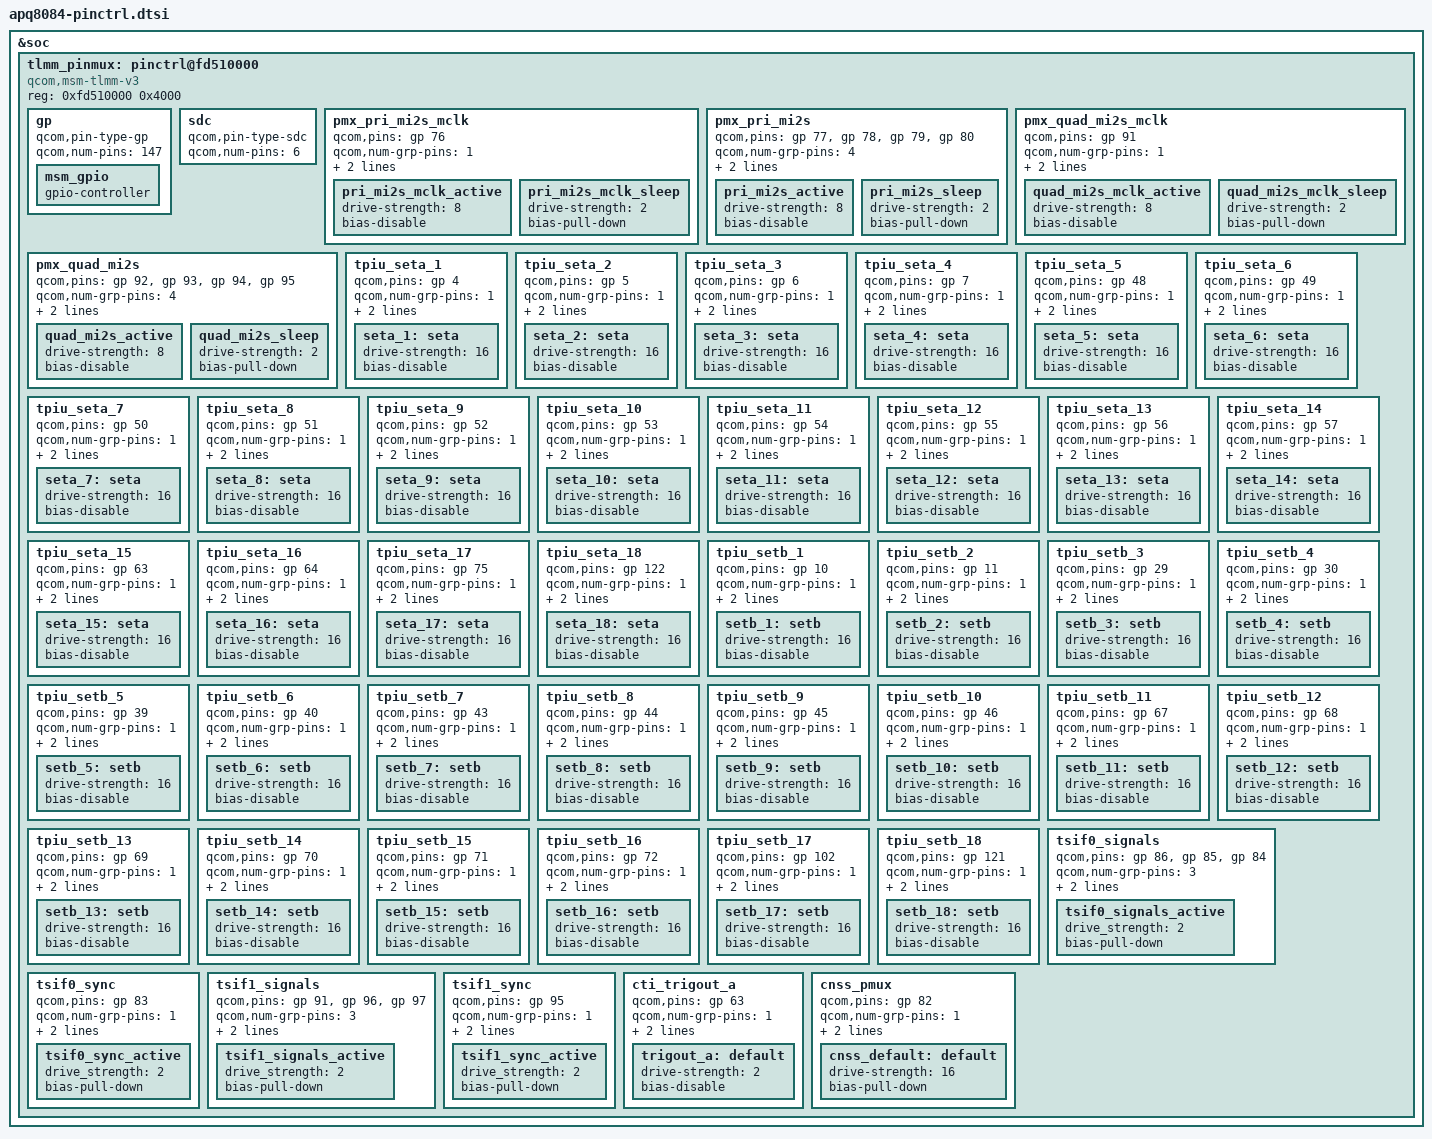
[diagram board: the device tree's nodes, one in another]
/* Copyright (c) 2014, The Linux Foundation. All rights reserved.
 *
 * This program is free software; you can redistribute it and/or modify
 * it under the terms of the GNU General Public License version 2 and
 * only version 2 as published by the Free Software Foundation.
 *
 * This program is distributed in the hope that it will be useful,
 * but WITHOUT ANY WARRANTY; without even the implied warranty of
 * MERCHANTABILITY or FITNESS FOR A PARTICULAR PURPOSE.  See the
 * GNU General Public License for more details.
 */

&soc {
	tlmm_pinmux: pinctrl@fd510000 {
		compatible = "qcom,msm-tlmm-v3";
		reg = <0xfd510000 0x4000>;

		/*General purpose pins*/
		gp: gp {
			qcom,pin-type-gp;
			qcom,num-pins = <147>;
			#qcom,pin-cells = <1>;
			msm_gpio: msm_gpio {
				gpio-controller;
				#gpio-cells = <2>;
			};
		};
		/* SDC pin type */
		sdc: sdc {
			qcom,pin-type-sdc;
			/* 0-2 for sdc1 3-5 for sdc2 */
			qcom,num-pins = <6>;
			/* Order of pins */
			/* CLK -> 0 */
			/* CMD -> 1 */
			/* DATA -> 2 */
			#qcom,pin-cells = <1>;
		};

		pmx_pri_mi2s_mclk {
			qcom,pins = <&gp 76>;
			qcom,num-grp-pins = <1>;
			qcom,pin-func = <1>;
			label = "pri_mi2s_mclk";
			pri_mi2s_mclk_active: pri_mi2s_mclk_active {
				drive-strength = <8>;	/* 8 MA */
				bias-disable;		/* No PULL */
		        };
			pri_mi2s_mclk_sleep: pri_mi2s_mclk_sleep {
				drive-strength = <2>;	/* 2 MA */
				bias-pull-down;		/* PULL DOWN */
		        };
		};

		pmx_pri_mi2s {
			qcom,pins = <&gp 77>, <&gp 78>, <&gp 79>, <&gp 80>;
			qcom,num-grp-pins = <4>;
			qcom,pin-func = <1>;
			label = "pri_mi2s";
			pri_mi2s_active: pri_mi2s_active {
				drive-strength = <8>;	/* 8 MA */
				bias-disable;		/* No PULL */
		        };
			pri_mi2s_sleep: pri_mi2s_sleep {
				drive-strength = <2>;	/* 2 MA */
				bias-pull-down;		/* PULL DOWN */
		        };
		};

		pmx_quad_mi2s_mclk {
			qcom,pins = <&gp 91>;
			qcom,num-grp-pins = <1>;
			qcom,pin-func = <1>;
			label = "quad_mi2s_mclk";
			quad_mi2s_mclk_active: quad_mi2s_mclk_active {
				drive-strength = <8>;	/* 8 MA */
				bias-disable;		/* No PULL */
		        };
			quad_mi2s_mclk_sleep: quad_mi2s_mclk_sleep {
				drive-strength = <2>;	/* 2 MA */
				bias-pull-down;		/* PULL DOWN */
		        };
		};

		pmx_quad_mi2s {
			qcom,pins = <&gp 92>, <&gp 93>, <&gp 94>, <&gp 95>;
			qcom,num-grp-pins = <4>;
			qcom,pin-func = <1>;
			label = "quad_mi2s";
			quad_mi2s_active: quad_mi2s_active {
				drive-strength = <8>;	/* 8 MA */
				bias-disable;		/* No PULL */
		        };
			quad_mi2s_sleep: quad_mi2s_sleep {
				drive-strength = <2>;	/* 2 MA */
				bias-pull-down;		/* PULL DOWN */
		        };
		};

		/* CoreSight */
		tpiu_seta_1 {
			qcom,pins = <&gp 4>;
			qcom,num-grp-pins = <1>;
			qcom,pin-func = <4>;
			label = "tpiu-seta-1";
			seta_1: seta {
				drive-strength = <16>;
				bias-disable;
			};
		};

		tpiu_seta_2 {
			qcom,pins = <&gp 5>;
			qcom,num-grp-pins = <1>;
			qcom,pin-func = <4>;
			label = "tpiu-seta-2";
			seta_2: seta {
				drive-strength = <16>;
				bias-disable;
			};
		};

		tpiu_seta_3 {
			qcom,pins = <&gp 6>;
			qcom,num-grp-pins = <1>;
			qcom,pin-func = <4>;
			label = "tpiu-seta-3";
			seta_3: seta {
				drive-strength = <16>;
				bias-disable;
			};
		};

		tpiu_seta_4 {
			qcom,pins = <&gp 7>;
			qcom,num-grp-pins = <1>;
			qcom,pin-func = <4>;
			label = "tpiu-seta-4";
			seta_4: seta {
				drive-strength = <16>;
				bias-disable;
			};
		};

		tpiu_seta_5 {
			qcom,pins = <&gp 48>;
			qcom,num-grp-pins = <1>;
			qcom,pin-func = <5>;
			label = "tpiu-seta-5";
			seta_5: seta {
				drive-strength = <16>;
				bias-disable;
			};
		};

		tpiu_seta_6 {
			qcom,pins = <&gp 49>;
			qcom,num-grp-pins = <1>;
			qcom,pin-func = <4>;
			label = "tpiu-seta-6";
			seta_6: seta {
				drive-strength = <16>;
				bias-disable;
			};
		};

		tpiu_seta_7 {
			qcom,pins = <&gp 50>;
			qcom,num-grp-pins = <1>;
			qcom,pin-func = <4>;
			label = "tpiu-seta-7";
			seta_7: seta {
				drive-strength = <16>;
				bias-disable;
			};
		};

		tpiu_seta_8 {
			qcom,pins = <&gp 51>;
			qcom,num-grp-pins = <1>;
			qcom,pin-func = <5>;
			label = "tpiu-seta-8";
			seta_8: seta {
				drive-strength = <16>;
				bias-disable;
			};
		};

		tpiu_seta_9 {
			qcom,pins = <&gp 52>;
			qcom,num-grp-pins = <1>;
			qcom,pin-func = <5>;
			label = "tpiu-seta-9";
			seta_9: seta {
				drive-strength = <16>;
				bias-disable;
			};
		};

		tpiu_seta_10 {
			qcom,pins = <&gp 53>;
			qcom,num-grp-pins = <1>;
			qcom,pin-func = <4>;
			label = "tpiu-seta-10";
			seta_10: seta {
				drive-strength = <16>;
				bias-disable;
			};
		};

		tpiu_seta_11 {
			qcom,pins = <&gp 54>;
			qcom,num-grp-pins = <1>;
			qcom,pin-func = <4>;
			label = "tpiu-seta-11";
			seta_11: seta {
				drive-strength = <16>;
				bias-disable;
			};
		};

		tpiu_seta_12 {
			qcom,pins = <&gp 55>;
			qcom,num-grp-pins = <1>;
			qcom,pin-func = <4>;
			label = "tpiu-seta-12";
			seta_12: seta {
				drive-strength = <16>;
				bias-disable;
			};
		};

		tpiu_seta_13 {
			qcom,pins = <&gp 56>;
			qcom,num-grp-pins = <1>;
			qcom,pin-func = <4>;
			label = "tpiu-seta-13";
			seta_13: seta {
				drive-strength = <16>;
				bias-disable;
			};
		};

		tpiu_seta_14 {
			qcom,pins = <&gp 57>;
			qcom,num-grp-pins = <1>;
			qcom,pin-func = <4>;
			label = "tpiu-seta-14";
			seta_14: seta {
				drive-strength = <16>;
				bias-disable;
			};
		};

		tpiu_seta_15 {
			qcom,pins = <&gp 63>;
			qcom,num-grp-pins = <1>;
			qcom,pin-func = <4>;
			label = "tpiu-seta-15";
			seta_15: seta {
				drive-strength = <16>;
				bias-disable;
			};
		};

		tpiu_seta_16 {
			qcom,pins = <&gp 64>;
			qcom,num-grp-pins = <1>;
			qcom,pin-func = <5>;
			label = "tpiu-seta-16";
			seta_16: seta {
				drive-strength = <16>;
				bias-disable;
			};
		};

		tpiu_seta_17 {
			qcom,pins = <&gp 75>;
			qcom,num-grp-pins = <1>;
			qcom,pin-func = <2>;
			label = "tpiu-seta-17";
			seta_17: seta {
				drive-strength = <16>;
				bias-disable;
			};
		};

		tpiu_seta_18 {
			qcom,pins = <&gp 122>;
			qcom,num-grp-pins = <1>;
			qcom,pin-func = <1>;
			label = "tpiu-seta-18";
			seta_18: seta {
				drive-strength = <16>;
				bias-disable;
			};
		};

		tpiu_setb_1 {
			qcom,pins = <&gp 10>;
			qcom,num-grp-pins = <1>;
			qcom,pin-func = <4>;
			label = "tpiu-setb-1";
			setb_1: setb {
				drive-strength = <16>;
				bias-disable;
			};
		};

		tpiu_setb_2 {
			qcom,pins = <&gp 11>;
			qcom,num-grp-pins = <1>;
			qcom,pin-func = <4>;
			label = "tpiu-setb-2";
			setb_2: setb {
				drive-strength = <16>;
				bias-disable;
			};
		};

		tpiu_setb_3 {
			qcom,pins = <&gp 29>;
			qcom,num-grp-pins = <1>;
			qcom,pin-func = <5>;
			label = "tpiu-setb-3";
			setb_3: setb {
				drive-strength = <16>;
				bias-disable;
			};
		};

		tpiu_setb_4 {
			qcom,pins = <&gp 30>;
			qcom,num-grp-pins = <1>;
			qcom,pin-func = <4>;
			label = "tpiu-setb-4";
			setb_4: setb {
				drive-strength = <16>;
				bias-disable;
			};
		};

		tpiu_setb_5 {
			qcom,pins = <&gp 39>;
			qcom,num-grp-pins = <1>;
			qcom,pin-func = <4>;
			label = "tpiu-setb-5";
			setb_5: setb {
				drive-strength = <16>;
				bias-disable;
			};
		};

		tpiu_setb_6 {
			qcom,pins = <&gp 40>;
			qcom,num-grp-pins = <1>;
			qcom,pin-func = <4>;
			label = "tpiu-setb-6";
			setb_6: setb {
				drive-strength = <16>;
				bias-disable;
			};
		};

		tpiu_setb_7 {
			qcom,pins = <&gp 43>;
			qcom,num-grp-pins = <1>;
			qcom,pin-func = <4>;
			label = "tpiu-setb-7";
			setb_7: setb {
				drive-strength = <16>;
				bias-disable;
			};
		};

		tpiu_setb_8 {
			qcom,pins = <&gp 44>;
			qcom,num-grp-pins = <1>;
			qcom,pin-func = <4>;
			label = "tpiu-setb-8";
			setb_8: setb {
				drive-strength = <16>;
				bias-disable;
			};
		};

		tpiu_setb_9 {
			qcom,pins = <&gp 45>;
			qcom,num-grp-pins = <1>;
			qcom,pin-func = <4>;
			label = "tpiu-setb-9";
			setb_9: setb {
				drive-strength = <16>;
				bias-disable;
			};
		};

		tpiu_setb_10 {
			qcom,pins = <&gp 46>;
			qcom,num-grp-pins = <1>;
			qcom,pin-func = <4>;
			label = "tpiu-setb-10";
			setb_10: setb {
				drive-strength = <16>;
				bias-disable;
			};
		};

		tpiu_setb_11 {
			qcom,pins = <&gp 67>;
			qcom,num-grp-pins = <1>;
			qcom,pin-func = <3>;
			label = "tpiu-setb-11";
			setb_11: setb {
				drive-strength = <16>;
				bias-disable;
			};
		};

		tpiu_setb_12 {
			qcom,pins = <&gp 68>;
			qcom,num-grp-pins = <1>;
			qcom,pin-func = <3>;
			label = "tpiu-setb-12";
			setb_12: setb {
				drive-strength = <16>;
				bias-disable;
			};
		};

		tpiu_setb_13 {
			qcom,pins = <&gp 69>;
			qcom,num-grp-pins = <1>;
			qcom,pin-func = <2>;
			label = "tpiu-setb-13";
			setb_13: setb {
				drive-strength = <16>;
				bias-disable;
			};
		};

		tpiu_setb_14 {
			qcom,pins = <&gp 70>;
			qcom,num-grp-pins = <1>;
			qcom,pin-func = <4>;
			label = "tpiu-setb-14";
			setb_14: setb {
				drive-strength = <16>;
				bias-disable;
			};
		};

		tpiu_setb_15 {
			qcom,pins = <&gp 71>;
			qcom,num-grp-pins = <1>;
			qcom,pin-func = <3>;
			label = "tpiu-setb-15";
			setb_15: setb {
				drive-strength = <16>;
				bias-disable;
			};
		};

		tpiu_setb_16 {
			qcom,pins = <&gp 72>;
			qcom,num-grp-pins = <1>;
			qcom,pin-func = <3>;
			label = "tpiu-setb-16";
			setb_16: setb {
				drive-strength = <16>;
				bias-disable;
			};
		};

		tpiu_setb_17 {
			qcom,pins = <&gp 102>;
			qcom,num-grp-pins = <1>;
			qcom,pin-func = <2>;
			label = "tpiu-setb-17";
			setb_17: setb {
				drive-strength = <16>;
				bias-disable;
			};
		};

		tpiu_setb_18 {
			qcom,pins = <&gp 121>;
			qcom,num-grp-pins = <1>;
			qcom,pin-func = <1>;
			label = "tpiu-setb-18";
			setb_18: setb {
				drive-strength = <16>;
				bias-disable;
			};
		};

		tsif0_signals {
			qcom,pins = <&gp 86>,	/* TSIF0 CLK */
				<&gp 85>,	/* TSIF0 Enable */
				<&gp 84>;	/* TSIF0 DATA */
			qcom,num-grp-pins = <3>;
			qcom,pins-func = <3>;
			label = "tsif0-signals";
			tsif0_signals_active: tsif0_signals_active {
				drive_strength = <2>;	/* 2 mA */
				bias-pull-down;		/* pull down */
			};
		};

		/* sync signal is only used in mode-2 */
		tsif0_sync {
			qcom,pins = <&gp 83>;	/* TSIF0 SYNC */
			qcom,num-grp-pins = <1>;
			qcom,pins-func = <3>;
			label = "tsif0-sync";
			tsif0_sync_active: tsif0_sync_active {
				drive_strength = <2>;	/* 2 mA */
				bias-pull-down;		/* pull down */
			};
		};

		tsif1_signals {
			qcom,pins = <&gp 91>,	/* TSIF1 CLK */
				<&gp 96>,	/* TSIF1 Enable */
				<&gp 97>;	/* TSIF1 DATA */
			qcom,num-grp-pins = <3>;
			qcom,pins-func = <3>;
			label = "tsif1-signals";
			tsif1_signals_active: tsif1_signals_active {
				drive_strength = <2>;	/* 2 mA */
				bias-pull-down;		/* pull down */
			};
		};

		/* sync signal is only used in mode-2 */
		tsif1_sync {
			qcom,pins = <&gp 95>;	/* TSIF1 SYNC */
			qcom,num-grp-pins = <1>;
			qcom,pins-func = <3>;
			label = "tsif1-sync";
			tsif1_sync_active: tsif1_sync_active {
				drive_strength = <2>;	/* 2 mA */
				bias-pull-down;		/* pull down */
			};
		};

		cti_trigout_a {
			qcom,pins = <&gp 63>;
			qcom,num-grp-pins = <1>;
			qcom,pin-func = <5>;
			label = "cti-trigout-a";
			trigout_a: default {
				drive-strength = <2>;
				bias-disable;
			};
		};

		cnss_pmux: cnss_pmux {
			qcom,pins = <&gp 82>;
			qcom,num-grp-pins = <1>;
			qcom,pin-func = <0>;
			label = "cnss_pins";
			cnss_default: default {
				drive-strength = <16>;
				bias-pull-down;
			};
		};
	};
};
